AUTOSAR XML (schema 00044)
package /ComponentTypes
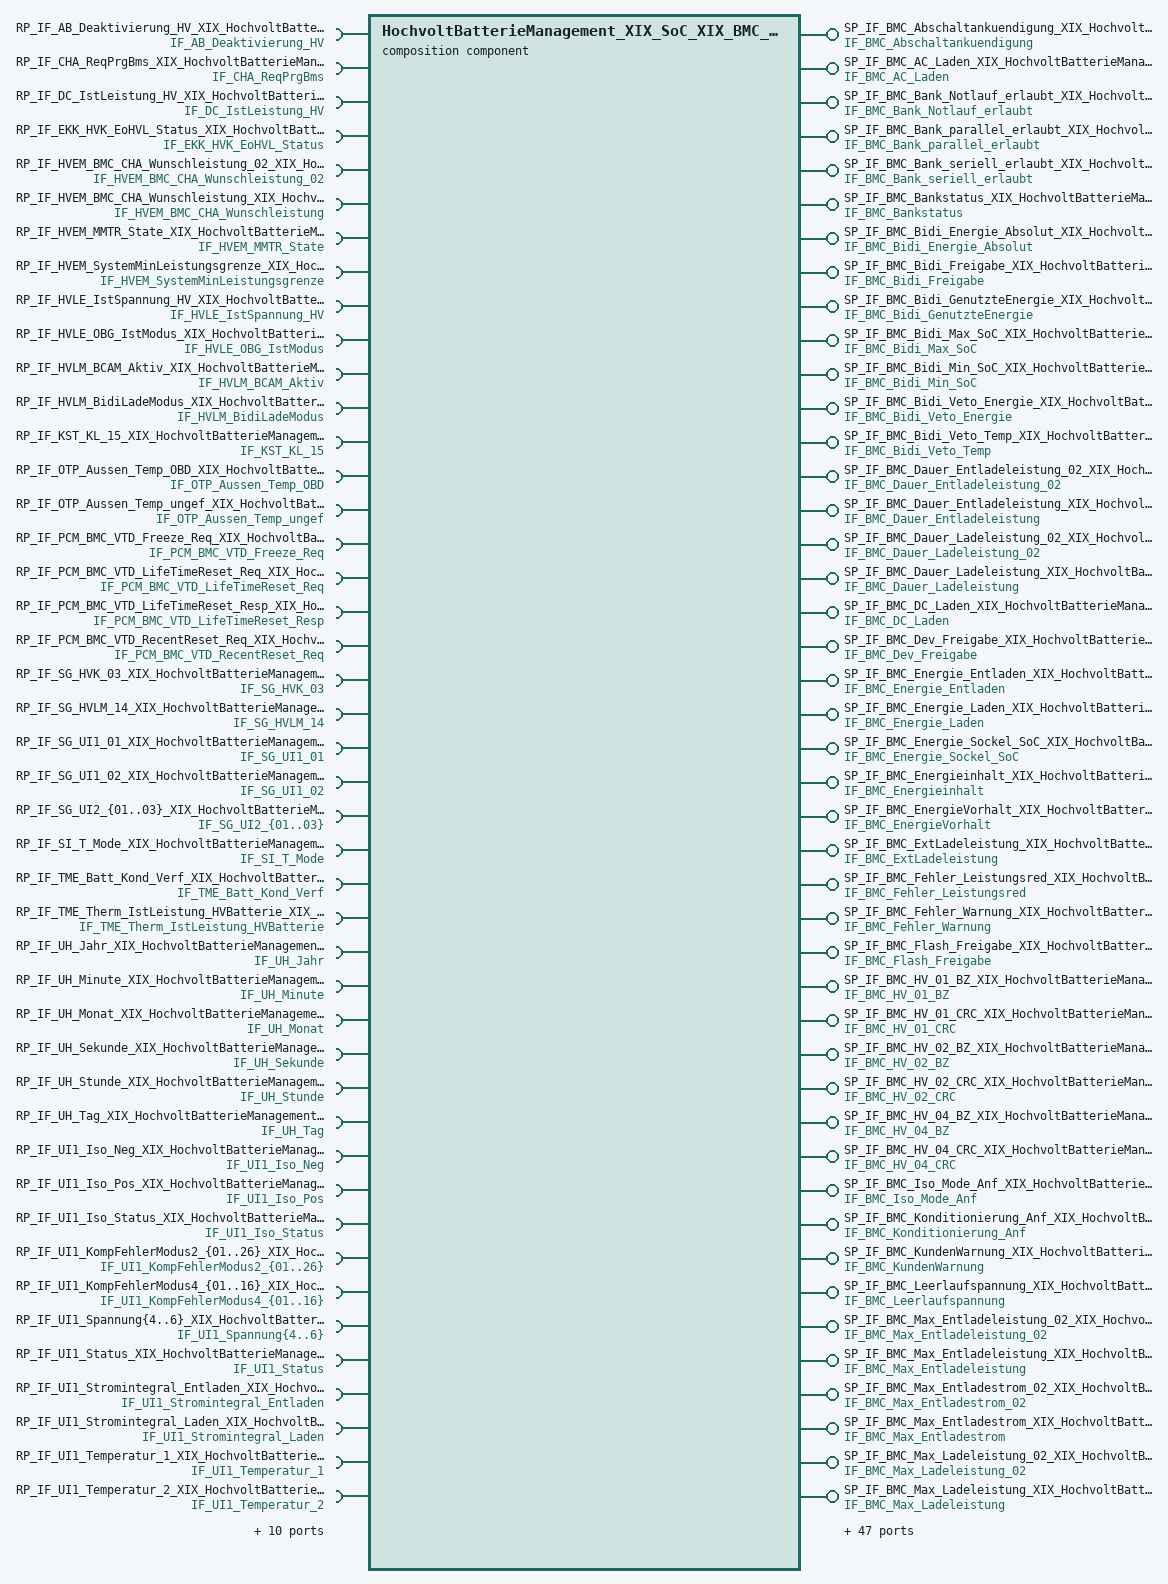
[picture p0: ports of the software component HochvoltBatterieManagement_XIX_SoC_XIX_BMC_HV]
  composition sw component type HochvoltBatterieManagement_XIX_SoC_XIX_BMC_HV
    91 x provide port:
      SP_IF_BMC_Abschaltankuendigung_XIX_HochvoltBatterieManagement_XIX_SoC_XIX_BMC_HV: nonqueued-sender-com-spec=DE_BMC_Abschaltankuendigung, provided-interface=IF_BMC_Abschaltankuendigung
      SP_IF_BMC_AC_Laden_XIX_HochvoltBatterieManagement_XIX_SoC_XIX_BMC_HV: nonqueued-sender-com-spec=DE_BMC_AC_Laden, provided-interface=IF_BMC_AC_Laden
      SP_IF_BMC_Bank_Notlauf_erlaubt_XIX_HochvoltBatterieManagement_XIX_SoC_XIX_BMC_HV: nonqueued-sender-com-spec=DE_BMC_Bank_Notlauf_erlaubt, provided-interface=IF_BMC_Bank_Notlauf_erlaubt
      SP_IF_BMC_Bank_parallel_erlaubt_XIX_HochvoltBatterieManagement_XIX_SoC_XIX_BMC_HV: nonqueued-sender-com-spec=DE_BMC_Bank_parallel_erlaubt, provided-interface=IF_BMC_Bank_parallel_erlaubt
      SP_IF_BMC_Bank_seriell_erlaubt_XIX_HochvoltBatterieManagement_XIX_SoC_XIX_BMC_HV: nonqueued-sender-com-spec=DE_BMC_Bank_seriell_erlaubt, provided-interface=IF_BMC_Bank_seriell_erlaubt
      SP_IF_BMC_Bankstatus_XIX_HochvoltBatterieManagement_XIX_SoC_XIX_BMC_HV: nonqueued-sender-com-spec=DE_BMC_Bankstatus, provided-interface=IF_BMC_Bankstatus
      SP_IF_BMC_Bidi_Energie_Absolut_XIX_HochvoltBatterieManagement_XIX_SoC_XIX_BMC_HV: nonqueued-sender-com-spec=DE_BMC_Bidi_Energie_Absolut, provided-interface=IF_BMC_Bidi_Energie_Absolut
      SP_IF_BMC_Bidi_Freigabe_XIX_HochvoltBatterieManagement_XIX_SoC_XIX_BMC_HV: nonqueued-sender-com-spec=DE_BMC_Bidi_Freigabe, provided-interface=IF_BMC_Bidi_Freigabe
      SP_IF_BMC_Bidi_GenutzteEnergie_XIX_HochvoltBatterieManagement_XIX_SoC_XIX_BMC_HV: nonqueued-sender-com-spec=DE_BMC_Bidi_GenutzteEnergie, provided-interface=IF_BMC_Bidi_GenutzteEnergie
      SP_IF_BMC_Bidi_Max_SoC_XIX_HochvoltBatterieManagement_XIX_SoC_XIX_BMC_HV: nonqueued-sender-com-spec=DE_BMC_Bidi_Max_SoC, provided-interface=IF_BMC_Bidi_Max_SoC
      SP_IF_BMC_Bidi_Min_SoC_XIX_HochvoltBatterieManagement_XIX_SoC_XIX_BMC_HV: nonqueued-sender-com-spec=DE_BMC_Bidi_Min_SoC, provided-interface=IF_BMC_Bidi_Min_SoC
      SP_IF_BMC_Bidi_Veto_Energie_XIX_HochvoltBatterieManagement_XIX_SoC_XIX_BMC_HV: nonqueued-sender-com-spec=DE_BMC_Bidi_Veto_Energie, provided-interface=IF_BMC_Bidi_Veto_Energie
      SP_IF_BMC_Bidi_Veto_Temp_XIX_HochvoltBatterieManagement_XIX_SoC_XIX_BMC_HV: nonqueued-sender-com-spec=DE_BMC_Bidi_Veto_Temp, provided-interface=IF_BMC_Bidi_Veto_Temp
      SP_IF_BMC_Dauer_Entladeleistung_02_XIX_HochvoltBatterieManagement_XIX_SoC_XIX_BMC_HV: nonqueued-sender-com-spec=DE_BMC_Dauer_Entladeleistung_02, provided-interface=IF_BMC_Dauer_Entladeleistung_02
      SP_IF_BMC_Dauer_Entladeleistung_XIX_HochvoltBatterieManagement_XIX_SoC_XIX_BMC_HV: nonqueued-sender-com-spec=DE_BMC_Dauer_Entladeleistung, provided-interface=IF_BMC_Dauer_Entladeleistung
      SP_IF_BMC_Dauer_Ladeleistung_02_XIX_HochvoltBatterieManagement_XIX_SoC_XIX_BMC_HV: nonqueued-sender-com-spec=DE_BMC_Dauer_Ladeleistung_02, provided-interface=IF_BMC_Dauer_Ladeleistung_02
      SP_IF_BMC_Dauer_Ladeleistung_XIX_HochvoltBatterieManagement_XIX_SoC_XIX_BMC_HV: nonqueued-sender-com-spec=DE_BMC_Dauer_Ladeleistung, provided-interface=IF_BMC_Dauer_Ladeleistung
      SP_IF_BMC_DC_Laden_XIX_HochvoltBatterieManagement_XIX_SoC_XIX_BMC_HV: nonqueued-sender-com-spec=DE_BMC_DC_Laden, provided-interface=IF_BMC_DC_Laden
      SP_IF_BMC_Dev_Freigabe_XIX_HochvoltBatterieManagement_XIX_SoC_XIX_BMC_HV: nonqueued-sender-com-spec=DE_BMC_Dev_Freigabe, provided-interface=IF_BMC_Dev_Freigabe
      SP_IF_BMC_Energie_Entladen_XIX_HochvoltBatterieManagement_XIX_SoC_XIX_BMC_HV: nonqueued-sender-com-spec=DE_BMC_Energie_Entladen, provided-interface=IF_BMC_Energie_Entladen
      SP_IF_BMC_Energie_Laden_XIX_HochvoltBatterieManagement_XIX_SoC_XIX_BMC_HV: nonqueued-sender-com-spec=DE_BMC_Energie_Laden, provided-interface=IF_BMC_Energie_Laden
      SP_IF_BMC_Energie_Sockel_SoC_XIX_HochvoltBatterieManagement_XIX_SoC_XIX_BMC_HV: nonqueued-sender-com-spec=DE_BMC_Energie_Sockel_SoC, provided-interface=IF_BMC_Energie_Sockel_SoC
      SP_IF_BMC_Energieinhalt_XIX_HochvoltBatterieManagement_XIX_SoC_XIX_BMC_HV: nonqueued-sender-com-spec=DE_BMC_Energieinhalt, provided-interface=IF_BMC_Energieinhalt
      SP_IF_BMC_EnergieVorhalt_XIX_HochvoltBatterieManagement_XIX_SoC_XIX_BMC_HV: nonqueued-sender-com-spec=DE_BMC_EnergieVorhalt, provided-interface=IF_BMC_EnergieVorhalt
      SP_IF_BMC_ExtLadeleistung_XIX_HochvoltBatterieManagement_XIX_SoC_XIX_BMC_HV: nonqueued-sender-com-spec=DE_BMC_ExtLadeleistung, provided-interface=IF_BMC_ExtLadeleistung
      SP_IF_BMC_Fehler_Leistungsred_XIX_HochvoltBatterieManagement_XIX_SoC_XIX_BMC_HV: nonqueued-sender-com-spec=DE_BMC_Fehler_Leistungsred, provided-interface=IF_BMC_Fehler_Leistungsred
      SP_IF_BMC_Fehler_Warnung_XIX_HochvoltBatterieManagement_XIX_SoC_XIX_BMC_HV: nonqueued-sender-com-spec=DE_BMC_Fehler_Warnung, provided-interface=IF_BMC_Fehler_Warnung
      SP_IF_BMC_Flash_Freigabe_XIX_HochvoltBatterieManagement_XIX_SoC_XIX_BMC_HV: nonqueued-sender-com-spec=DE_BMC_Flash_Freigabe, provided-interface=IF_BMC_Flash_Freigabe
      SP_IF_BMC_HV_01_BZ_XIX_HochvoltBatterieManagement_XIX_SoC_XIX_BMC_HV: nonqueued-sender-com-spec=DE_BMC_HV_01_BZ, provided-interface=IF_BMC_HV_01_BZ
      SP_IF_BMC_HV_01_CRC_XIX_HochvoltBatterieManagement_XIX_SoC_XIX_BMC_HV: nonqueued-sender-com-spec=DE_BMC_HV_01_CRC, provided-interface=IF_BMC_HV_01_CRC
      SP_IF_BMC_HV_02_BZ_XIX_HochvoltBatterieManagement_XIX_SoC_XIX_BMC_HV: nonqueued-sender-com-spec=DE_BMC_HV_02_BZ, provided-interface=IF_BMC_HV_02_BZ
      SP_IF_BMC_HV_02_CRC_XIX_HochvoltBatterieManagement_XIX_SoC_XIX_BMC_HV: nonqueued-sender-com-spec=DE_BMC_HV_02_CRC, provided-interface=IF_BMC_HV_02_CRC
      SP_IF_BMC_HV_04_BZ_XIX_HochvoltBatterieManagement_XIX_SoC_XIX_BMC_HV: nonqueued-sender-com-spec=DE_BMC_HV_04_BZ, provided-interface=IF_BMC_HV_04_BZ
      SP_IF_BMC_HV_04_CRC_XIX_HochvoltBatterieManagement_XIX_SoC_XIX_BMC_HV: nonqueued-sender-com-spec=DE_BMC_HV_04_CRC, provided-interface=IF_BMC_HV_04_CRC
      SP_IF_BMC_Iso_Mode_Anf_XIX_HochvoltBatterieManagement_XIX_SoC_XIX_BMC_HV: nonqueued-sender-com-spec=DE_BMC_Iso_Mode_Anf, provided-interface=IF_BMC_Iso_Mode_Anf
      SP_IF_BMC_Konditionierung_Anf_XIX_HochvoltBatterieManagement_XIX_SoC_XIX_BMC_HV: nonqueued-sender-com-spec=DE_BMC_Konditionierung_Anf, provided-interface=IF_BMC_Konditionierung_Anf
      SP_IF_BMC_KundenWarnung_XIX_HochvoltBatterieManagement_XIX_SoC_XIX_BMC_HV: nonqueued-sender-com-spec=DE_BMC_KundenWarnung, provided-interface=IF_BMC_KundenWarnung
      SP_IF_BMC_Leerlaufspannung_XIX_HochvoltBatterieManagement_XIX_SoC_XIX_BMC_HV: nonqueued-sender-com-spec=DE_BMC_Leerlaufspannung, provided-interface=IF_BMC_Leerlaufspannung
      SP_IF_BMC_Max_Entladeleistung_02_XIX_HochvoltBatterieManagement_XIX_SoC_XIX_BMC_HV: nonqueued-sender-com-spec=DE_BMC_Max_Entladeleistung_02, provided-interface=IF_BMC_Max_Entladeleistung_02
      SP_IF_BMC_Max_Entladeleistung_XIX_HochvoltBatterieManagement_XIX_SoC_XIX_BMC_HV: nonqueued-sender-com-spec=DE_BMC_Max_Entladeleistung, provided-interface=IF_BMC_Max_Entladeleistung
      SP_IF_BMC_Max_Entladestrom_02_XIX_HochvoltBatterieManagement_XIX_SoC_XIX_BMC_HV: nonqueued-sender-com-spec=DE_BMC_Max_Entladestrom_02, provided-interface=IF_BMC_Max_Entladestrom_02
      SP_IF_BMC_Max_Entladestrom_XIX_HochvoltBatterieManagement_XIX_SoC_XIX_BMC_HV: nonqueued-sender-com-spec=DE_BMC_Max_Entladestrom, provided-interface=IF_BMC_Max_Entladestrom
      SP_IF_BMC_Max_Ladeleistung_02_XIX_HochvoltBatterieManagement_XIX_SoC_XIX_BMC_HV: nonqueued-sender-com-spec=DE_BMC_Max_Ladeleistung_02, provided-interface=IF_BMC_Max_Ladeleistung_02
      SP_IF_BMC_Max_Ladeleistung_XIX_HochvoltBatterieManagement_XIX_SoC_XIX_BMC_HV: nonqueued-sender-com-spec=DE_BMC_Max_Ladeleistung, provided-interface=IF_BMC_Max_Ladeleistung
      SP_IF_BMC_Max_Ladestrom_02_XIX_HochvoltBatterieManagement_XIX_SoC_XIX_BMC_HV: nonqueued-sender-com-spec=DE_BMC_Max_Ladestrom_02, provided-interface=IF_BMC_Max_Ladestrom_02
      SP_IF_BMC_Max_Ladestrom_XIX_HochvoltBatterieManagement_XIX_SoC_XIX_BMC_HV: nonqueued-sender-com-spec=DE_BMC_Max_Ladestrom, provided-interface=IF_BMC_Max_Ladestrom
      SP_IF_BMC_Max_Spannung_XIX_HochvoltBatterieManagement_XIX_SoC_XIX_BMC_HV: nonqueued-sender-com-spec=DE_BMC_Max_Spannung, provided-interface=IF_BMC_Max_Spannung
      SP_IF_BMC_MaxEnergieinhalt_XIX_HochvoltBatterieManagement_XIX_SoC_XIX_BMC_HV: nonqueued-sender-com-spec=DE_BMC_MaxEnergieinhalt, provided-interface=IF_BMC_MaxEnergieinhalt
      SP_IF_BMC_Min_Spannung_XIX_HochvoltBatterieManagement_XIX_SoC_XIX_BMC_HV: nonqueued-sender-com-spec=DE_BMC_Min_Spannung, provided-interface=IF_BMC_Min_Spannung
      SP_IF_BMC_MinDyn_Entladespannung_XIX_HochvoltBatterieManagement_XIX_SoC_XIX_BMC_HV: nonqueued-sender-com-spec=DE_BMC_MinDyn_Entladespannung, provided-interface=IF_BMC_MinDyn_Entladespannung
      SP_IF_BMC_MinDyn_Ladespannung_XIX_HochvoltBatterieManagement_XIX_SoC_XIX_BMC_HV: nonqueued-sender-com-spec=DE_BMC_MinDyn_Ladespannung, provided-interface=IF_BMC_MinDyn_Ladespannung
      SP_IF_BMC_MMTR_Status_XIX_HochvoltBatterieManagement_XIX_SoC_XIX_BMC_HV: nonqueued-sender-com-spec=DE_BMC_MMTR_Status, provided-interface=IF_BMC_MMTR_Status
      SP_IF_BMC_NutzbareKapazitaet_XIX_HochvoltBatterieManagement_XIX_SoC_XIX_BMC_HV: nonqueued-sender-com-spec=DE_BMC_NutzbareKapazitaet, provided-interface=IF_BMC_NutzbareKapazitaet
      SP_IF_BMC_NutzbarerSOC_XIX_HochvoltBatterieManagement_XIX_SoC_XIX_BMC_HV: nonqueued-sender-com-spec=DE_BMC_NutzbarerSOC, provided-interface=IF_BMC_NutzbarerSOC
      SP_IF_BMC_PCM_VTD_Freeze_Req_XIX_HochvoltBatterieManagement_XIX_SoC_XIX_BMC_HV: nonqueued-sender-com-spec=DE_BMC_PCM_VTD_Freeze_Req, provided-interface=IF_BMC_PCM_VTD_Freeze_Req
      SP_IF_BMC_PCM_VTD_LifeTimeReset_Req_XIX_HochvoltBatterieManagement_XIX_SoC_XIX_BMC_HV: nonqueued-sender-com-spec=DE_BMC_PCM_VTD_LifeTimeReset_Req, provided-interface=IF_BMC_PCM_VTD_LifeTimeReset_Req
      SP_IF_BMC_PCM_VTD_LifeTimeReset_Resp_XIX_HochvoltBatterieManagement_XIX_SoC_XIX_BMC_HV: nonqueued-sender-com-spec=DE_BMC_PCM_VTD_LifeTimeReset_Resp, provided-interface=IF_BMC_PCM_VTD_LifeTimeReset_Resp
      SP_IF_BMC_PCM_VTD_RecentReset_Req_XIX_HochvoltBatterieManagement_XIX_SoC_XIX_BMC_HV: nonqueued-sender-com-spec=DE_BMC_PCM_VTD_RecentReset_Req, provided-interface=IF_BMC_PCM_VTD_RecentReset_Req
      SP_IF_BMC_PerfInd_Entladen_XIX_HochvoltBatterieManagement_XIX_SoC_XIX_BMC_HV: nonqueued-sender-com-spec=DE_BMC_PerfInd_Entladen, provided-interface=IF_BMC_PerfInd_Entladen
      SP_IF_BMC_PerfInd_Laden_XIX_HochvoltBatterieManagement_XIX_SoC_XIX_BMC_HV: nonqueued-sender-com-spec=DE_BMC_PerfInd_Laden, provided-interface=IF_BMC_PerfInd_Laden
      SP_IF_BMC_PredLeistung_StuetzungNV_XIX_HochvoltBatterieManagement_XIX_SoC_XIX_BMC_HV: nonqueued-sender-com-spec=DE_BMC_PredLeistung_StuetzungNV, provided-interface=IF_BMC_PredLeistung_StuetzungNV
      SP_IF_BMC_Range_Indikator_XIX_HochvoltBatterieManagement_XIX_SoC_XIX_BMC_HV: nonqueued-sender-com-spec=DE_BMC_Range_Indikator, provided-interface=IF_BMC_Range_Indikator
      SP_IF_BMC_Rekuperation_Ueberlauf_XIX_HochvoltBatterieManagement_XIX_SoC_XIX_BMC_HV: nonqueued-sender-com-spec=DE_BMC_Rekuperation_Ueberlauf, provided-interface=IF_BMC_Rekuperation_Ueberlauf
      SP_IF_BMC_Rekuperation_XIX_HochvoltBatterieManagement_XIX_SoC_XIX_BMC_HV: nonqueued-sender-com-spec=DE_BMC_Rekuperation, provided-interface=IF_BMC_Rekuperation
      SP_IF_BMC_RuecklaufTemperatur_XIX_HochvoltBatterieManagement_XIX_SoC_XIX_BMC_HV: nonqueued-sender-com-spec=DE_BMC_RuecklaufTemperatur, provided-interface=IF_BMC_RuecklaufTemperatur
      SP_IF_BMC_Spannung_DC_Ladesaeule_XIX_HochvoltBatterieManagement_XIX_SoC_XIX_BMC_HV: nonqueued-sender-com-spec=DE_BMC_Spannung_DC_Ladesaeule, provided-interface=IF_BMC_Spannung_DC_Ladesaeule
      SP_IF_BMC_Spannung_XIX_HochvoltBatterieManagement_XIX_SoC_XIX_BMC_HV: nonqueued-sender-com-spec=DE_BMC_Spannung, provided-interface=IF_BMC_Spannung
      SP_IF_BMC_Spannung_ZwischenKreis_2_XIX_HochvoltBatterieManagement_XIX_SoC_XIX_BMC_HV: nonqueued-sender-com-spec=DE_BMC_Spannung_ZwischenKreis_2, provided-interface=IF_BMC_Spannung_ZwischenKreis_2
      SP_IF_BMC_Spannung_ZwischenKreis_XIX_HochvoltBatterieManagement_XIX_SoC_XIX_BMC_HV: nonqueued-sender-com-spec=DE_BMC_Spannung_ZwischenKreis, provided-interface=IF_BMC_Spannung_ZwischenKreis
      SP_IF_BMC_Status_DCLS_XIX_HochvoltBatterieManagement_XIX_SoC_XIX_BMC_HV: nonqueued-sender-com-spec=DE_BMC_Status_DCLS, provided-interface=IF_BMC_Status_DCLS
      SP_IF_BMC_Strom_02_XIX_HochvoltBatterieManagement_XIX_SoC_XIX_BMC_HV: nonqueued-sender-com-spec=DE_BMC_Strom_02, provided-interface=IF_BMC_Strom_02
      SP_IF_BMC_Strom_XIX_HochvoltBatterieManagement_XIX_SoC_XIX_BMC_HV: nonqueued-sender-com-spec=DE_BMC_Strom, provided-interface=IF_BMC_Strom
      SP_IF_BMC_TechnischerSOC_XIX_HochvoltBatterieManagement_XIX_SoC_XIX_BMC_HV: nonqueued-sender-com-spec=DE_BMC_TechnischerSOC, provided-interface=IF_BMC_TechnischerSOC
      SP_IF_BMC_Temperatur_XIX_HochvoltBatterieManagement_XIX_SoC_XIX_BMC_HV: nonqueued-sender-com-spec=DE_BMC_Temperatur, provided-interface=IF_BMC_Temperatur
      SP_IF_BMC_ThermAuslastung_XIX_HochvoltBatterieManagement_XIX_SoC_XIX_BMC_HV: nonqueued-sender-com-spec=DE_BMC_ThermAuslastung, provided-interface=IF_BMC_ThermAuslastung
      SP_IF_BMC_ThermSpreizung_XIX_HochvoltBatterieManagement_XIX_SoC_XIX_BMC_HV: nonqueued-sender-com-spec=DE_BMC_ThermSpreizung, provided-interface=IF_BMC_ThermSpreizung
      SP_IF_BMC_UBE_Indik_last_update_km_XIX_HochvoltBatterieManagement_XIX_SoC_XIX_BMC_HV: nonqueued-sender-com-spec=DE_BMC_UBE_Indik_last_update_km, provided-interface=IF_BMC_UBE_Indik_last_update_km
      SP_IF_BMC_UBE_Indikator_XIX_HochvoltBatterieManagement_XIX_SoC_XIX_BMC_HV: nonqueued-sender-com-spec=DE_BMC_UBE_Indikator, provided-interface=IF_BMC_UBE_Indikator
      SP_IF_BMC_UI1_Spannung1_Schalt_Anf_XIX_HochvoltBatterieManagement_XIX_SoC_XIX_BMC_HV: nonqueued-sender-com-spec=DE_BMC_UI1_Spannung1_Schalt_Anf, provided-interface=IF_BMC_UI1_Spannung1_Schalt_Anf
      SP_IF_BMC_UI1_Spannung2_Schalt_Anf_XIX_HochvoltBatterieManagement_XIX_SoC_XIX_BMC_HV: nonqueued-sender-com-spec=DE_BMC_UI1_Spannung2_Schalt_Anf, provided-interface=IF_BMC_UI1_Spannung2_Schalt_Anf
      SP_IF_BMC_UI2_Spannung1_Schalt_Anf_XIX_HochvoltBatterieManagement_XIX_SoC_XIX_BMC_HV: nonqueued-sender-com-spec=DE_BMC_UI2_Spannung1_Schalt_Anf, provided-interface=IF_BMC_UI2_Spannung1_Schalt_Anf
      SP_IF_BMC_UI2_Spannung2_Schalt_Anf_XIX_HochvoltBatterieManagement_XIX_SoC_XIX_BMC_HV: nonqueued-sender-com-spec=DE_BMC_UI2_Spannung2_Schalt_Anf, provided-interface=IF_BMC_UI2_Spannung2_Schalt_Anf
      SP_IF_BMC_Unterboden_Warnung_XIX_HochvoltBatterieManagement_XIX_SoC_XIX_BMC_HV: nonqueued-sender-com-spec=DE_BMC_Unterboden_Warnung, provided-interface=IF_BMC_Unterboden_Warnung
      SP_IF_BMC_Verbauinfo_ACSchuetz_XIX_HochvoltBatterieManagement_XIX_SoC_XIX_BMC_HV: nonqueued-sender-com-spec=DE_BMC_Verbauinfo_ACSchuetz, provided-interface=IF_BMC_Verbauinfo_ACSchuetz
      SP_IF_BMC_Verbauinfo_Bank_XIX_HochvoltBatterieManagement_XIX_SoC_XIX_BMC_HV: nonqueued-sender-com-spec=DE_BMC_Verbauinfo_Bank, provided-interface=IF_BMC_Verbauinfo_Bank
      SP_IF_BMC_Verbrauch_Ueberlauf_XIX_HochvoltBatterieManagement_XIX_SoC_XIX_BMC_HV: nonqueued-sender-com-spec=DE_BMC_Verbrauch_Ueberlauf, provided-interface=IF_BMC_Verbrauch_Ueberlauf
      SP_IF_BMC_Verbrauch_XIX_HochvoltBatterieManagement_XIX_SoC_XIX_BMC_HV: nonqueued-sender-com-spec=DE_BMC_Verbrauch, provided-interface=IF_BMC_Verbrauch
      SP_IF_BMC_VerlustEnergie_XIX_HochvoltBatterieManagement_XIX_SoC_XIX_BMC_HV: nonqueued-sender-com-spec=DE_BMC_VerlustEnergie, provided-interface=IF_BMC_VerlustEnergie
      SP_IF_BMC_VorlaufTemperatur_XIX_HochvoltBatterieManagement_XIX_SoC_XIX_BMC_HV: nonqueued-sender-com-spec=DE_BMC_VorlaufTemperatur, provided-interface=IF_BMC_VorlaufTemperatur
      SP_IF_BMC_ZellTemp_virtuell_max_XIX_HochvoltBatterieManagement_XIX_SoC_XIX_BMC_HV: nonqueued-sender-com-spec=DE_BMC_ZellTemp_virtuell_max, provided-interface=IF_BMC_ZellTemp_virtuell_max
      SP_IF_BMC_ZellTemp_virtuell_min_XIX_HochvoltBatterieManagement_XIX_SoC_XIX_BMC_HV: nonqueued-sender-com-spec=DE_BMC_ZellTemp_virtuell_min, provided-interface=IF_BMC_ZellTemp_virtuell_min
    138 x require port:
      RP_IF_AB_Deaktivierung_HV_XIX_HochvoltBatterieManagement_XIX_SoC_XIX_BMC_HV: nonqueued-receiver-com-spec=DE_AB_Deaktivierung_HV, required-interface=IF_AB_Deaktivierung_HV
      RP_IF_CHA_ReqPrgBms_XIX_HochvoltBatterieManagement_XIX_SoC_XIX_BMC_HV: nonqueued-receiver-com-spec=DE_CHA_ReqPrgBms, required-interface=IF_CHA_ReqPrgBms
      RP_IF_DC_IstLeistung_HV_XIX_HochvoltBatterieManagement_XIX_SoC_XIX_BMC_HV: nonqueued-receiver-com-spec=DE_DC_IstLeistung_HV, required-interface=IF_DC_IstLeistung_HV
      RP_IF_EKK_HVK_EoHVL_Status_XIX_HochvoltBatterieManagement_XIX_SoC_XIX_BMC_HV: nonqueued-receiver-com-spec=DE_EKK_HVK_EoHVL_Status, required-interface=IF_EKK_HVK_EoHVL_Status
      RP_IF_HVEM_BMC_CHA_Wunschleistung_02_XIX_HochvoltBatterieManagement_XIX_SoC_XIX_BMC_HV: nonqueued-receiver-com-spec=DE_HVEM_BMC_CHA_Wunschleistung_02, required-interface=IF_HVEM_BMC_CHA_Wunschleistung_02
      RP_IF_HVEM_BMC_CHA_Wunschleistung_XIX_HochvoltBatterieManagement_XIX_SoC_XIX_BMC_HV: nonqueued-receiver-com-spec=DE_HVEM_BMC_CHA_Wunschleistung, required-interface=IF_HVEM_BMC_CHA_Wunschleistung
      RP_IF_HVEM_MMTR_State_XIX_HochvoltBatterieManagement_XIX_SoC_XIX_BMC_HV: nonqueued-receiver-com-spec=DE_HVEM_MMTR_State, required-interface=IF_HVEM_MMTR_State
      RP_IF_HVEM_SystemMinLeistungsgrenze_XIX_HochvoltBatterieManagement_XIX_SoC_XIX_BMC_HV: nonqueued-receiver-com-spec=DE_HVEM_SystemMinLeistungsgrenze, required-interface=IF_HVEM_SystemMinLeistungsgrenze
      RP_IF_HVLE_IstSpannung_HV_XIX_HochvoltBatterieManagement_XIX_SoC_XIX_BMC_HV: nonqueued-receiver-com-spec=DE_HVLE_IstSpannung_HV, required-interface=IF_HVLE_IstSpannung_HV
      RP_IF_HVLE_OBG_IstModus_XIX_HochvoltBatterieManagement_XIX_SoC_XIX_BMC_HV: nonqueued-receiver-com-spec=DE_HVLE_OBG_IstModus, required-interface=IF_HVLE_OBG_IstModus
      RP_IF_HVLM_BCAM_Aktiv_XIX_HochvoltBatterieManagement_XIX_SoC_XIX_BMC_HV: nonqueued-receiver-com-spec=DE_HVLM_BCAM_Aktiv, required-interface=IF_HVLM_BCAM_Aktiv
      RP_IF_HVLM_BidiLadeModus_XIX_HochvoltBatterieManagement_XIX_SoC_XIX_BMC_HV: nonqueued-receiver-com-spec=DE_HVLM_BidiLadeModus, required-interface=IF_HVLM_BidiLadeModus
      RP_IF_KST_KL_15_XIX_HochvoltBatterieManagement_XIX_SoC_XIX_BMC_HV: nonqueued-receiver-com-spec=DE_KST_KL_15, required-interface=IF_KST_KL_15
      RP_IF_OTP_Aussen_Temp_OBD_XIX_HochvoltBatterieManagement_XIX_SoC_XIX_BMC_HV: nonqueued-receiver-com-spec=DE_OTP_Aussen_Temp_OBD, required-interface=IF_OTP_Aussen_Temp_OBD
      RP_IF_OTP_Aussen_Temp_ungef_XIX_HochvoltBatterieManagement_XIX_SoC_XIX_BMC_HV: nonqueued-receiver-com-spec=DE_OTP_Aussen_Temp_ungef, required-interface=IF_OTP_Aussen_Temp_ungef
      RP_IF_PCM_BMC_VTD_Freeze_Req_XIX_HochvoltBatterieManagement_XIX_SoC_XIX_BMC_HV: nonqueued-receiver-com-spec=DE_PCM_BMC_VTD_Freeze_Req, required-interface=IF_PCM_BMC_VTD_Freeze_Req
      RP_IF_PCM_BMC_VTD_LifeTimeReset_Req_XIX_HochvoltBatterieManagement_XIX_SoC_XIX_BMC_HV: nonqueued-receiver-com-spec=DE_PCM_BMC_VTD_LifeTimeReset_Req, required-interface=IF_PCM_BMC_VTD_LifeTimeReset_Req
      RP_IF_PCM_BMC_VTD_LifeTimeReset_Resp_XIX_HochvoltBatterieManagement_XIX_SoC_XIX_BMC_HV: nonqueued-receiver-com-spec=DE_PCM_BMC_VTD_LifeTimeReset_Resp, required-interface=IF_PCM_BMC_VTD_LifeTimeReset_Resp
      RP_IF_PCM_BMC_VTD_RecentReset_Req_XIX_HochvoltBatterieManagement_XIX_SoC_XIX_BMC_HV: nonqueued-receiver-com-spec=DE_PCM_BMC_VTD_RecentReset_Req, required-interface=IF_PCM_BMC_VTD_RecentReset_Req
      RP_IF_SG_HVK_03_XIX_HochvoltBatterieManagement_XIX_SoC_XIX_BMC_HV: nonqueued-receiver-com-spec=DE_SG_HVK_03, required-interface=IF_SG_HVK_03
      RP_IF_SG_HVLM_14_XIX_HochvoltBatterieManagement_XIX_SoC_XIX_BMC_HV: nonqueued-receiver-com-spec=DE_SG_HVLM_14, required-interface=IF_SG_HVLM_14
      RP_IF_SG_UI1_01_XIX_HochvoltBatterieManagement_XIX_SoC_XIX_BMC_HV: nonqueued-receiver-com-spec=DE_SG_UI1_01, required-interface=IF_SG_UI1_01
      RP_IF_SG_UI1_02_XIX_HochvoltBatterieManagement_XIX_SoC_XIX_BMC_HV: nonqueued-receiver-com-spec=DE_SG_UI1_02, required-interface=IF_SG_UI1_02
      RP_IF_SG_UI2_{01..03}_XIX_HochvoltBatterieManagement_XIX_SoC_XIX_BMC_HV: nonqueued-receiver-com-spec=DE_SG_UI2_{01..03}, required-interface=IF_SG_UI2_{01..03}
      RP_IF_SI_T_Mode_XIX_HochvoltBatterieManagement_XIX_SoC_XIX_BMC_HV: nonqueued-receiver-com-spec=DE_SI_T_Mode, required-interface=IF_SI_T_Mode
      RP_IF_TME_Batt_Kond_Verf_XIX_HochvoltBatterieManagement_XIX_SoC_XIX_BMC_HV: nonqueued-receiver-com-spec=DE_TME_Batt_Kond_Verf, required-interface=IF_TME_Batt_Kond_Verf
      RP_IF_TME_Therm_IstLeistung_HVBatterie_XIX_HochvoltBatterieManagement_XIX_SoC_XIX_BMC_HV: nonqueued-receiver-com-spec=DE_TME_Therm_IstLeistung_HVBatterie, required-interface=IF_TME_Therm_IstLeistung_HVBatterie
      RP_IF_UH_Jahr_XIX_HochvoltBatterieManagement_XIX_SoC_XIX_BMC_HV: nonqueued-receiver-com-spec=DE_UH_Jahr, required-interface=IF_UH_Jahr
      RP_IF_UH_Minute_XIX_HochvoltBatterieManagement_XIX_SoC_XIX_BMC_HV: nonqueued-receiver-com-spec=DE_UH_Minute, required-interface=IF_UH_Minute
      RP_IF_UH_Monat_XIX_HochvoltBatterieManagement_XIX_SoC_XIX_BMC_HV: nonqueued-receiver-com-spec=DE_UH_Monat, required-interface=IF_UH_Monat
      RP_IF_UH_Sekunde_XIX_HochvoltBatterieManagement_XIX_SoC_XIX_BMC_HV: nonqueued-receiver-com-spec=DE_UH_Sekunde, required-interface=IF_UH_Sekunde
      RP_IF_UH_Stunde_XIX_HochvoltBatterieManagement_XIX_SoC_XIX_BMC_HV: nonqueued-receiver-com-spec=DE_UH_Stunde, required-interface=IF_UH_Stunde
      RP_IF_UH_Tag_XIX_HochvoltBatterieManagement_XIX_SoC_XIX_BMC_HV: nonqueued-receiver-com-spec=DE_UH_Tag, required-interface=IF_UH_Tag
      RP_IF_UI1_Iso_Neg_XIX_HochvoltBatterieManagement_XIX_SoC_XIX_BMC_HV: nonqueued-receiver-com-spec=DE_UI1_Iso_Neg, required-interface=IF_UI1_Iso_Neg
      RP_IF_UI1_Iso_Pos_XIX_HochvoltBatterieManagement_XIX_SoC_XIX_BMC_HV: nonqueued-receiver-com-spec=DE_UI1_Iso_Pos, required-interface=IF_UI1_Iso_Pos
      RP_IF_UI1_Iso_Status_XIX_HochvoltBatterieManagement_XIX_SoC_XIX_BMC_HV: nonqueued-receiver-com-spec=DE_UI1_Iso_Status, required-interface=IF_UI1_Iso_Status
      RP_IF_UI1_KompFehlerModus2_{01..26}_XIX_HochvoltBatterieManagement_XIX_SoC_XIX_BMC_HV: nonqueued-receiver-com-spec=DE_UI1_KompFehlerModus2_{01..26}, required-interface=IF_UI1_KompFehlerModus2_{01..26}
      RP_IF_UI1_KompFehlerModus4_{01..16}_XIX_HochvoltBatterieManagement_XIX_SoC_XIX_BMC_HV: nonqueued-receiver-com-spec=DE_UI1_KompFehlerModus4_{01..16}, required-interface=IF_UI1_KompFehlerModus4_{01..16}
      RP_IF_UI1_Spannung{4..6}_XIX_HochvoltBatterieManagement_XIX_SoC_XIX_BMC_HV: nonqueued-receiver-com-spec=DE_UI1_Spannung{4..6}, required-interface=IF_UI1_Spannung{4..6}
      RP_IF_UI1_Status_XIX_HochvoltBatterieManagement_XIX_SoC_XIX_BMC_HV: nonqueued-receiver-com-spec=DE_UI1_Status, required-interface=IF_UI1_Status
      RP_IF_UI1_Stromintegral_Entladen_XIX_HochvoltBatterieManagement_XIX_SoC_XIX_BMC_HV: nonqueued-receiver-com-spec=DE_UI1_Stromintegral_Entladen, required-interface=IF_UI1_Stromintegral_Entladen
      RP_IF_UI1_Stromintegral_Laden_XIX_HochvoltBatterieManagement_XIX_SoC_XIX_BMC_HV: nonqueued-receiver-com-spec=DE_UI1_Stromintegral_Laden, required-interface=IF_UI1_Stromintegral_Laden
      RP_IF_UI1_Temperatur_1_XIX_HochvoltBatterieManagement_XIX_SoC_XIX_BMC_HV: nonqueued-receiver-com-spec=DE_UI1_Temperatur_1, required-interface=IF_UI1_Temperatur_1
      RP_IF_UI1_Temperatur_2_XIX_HochvoltBatterieManagement_XIX_SoC_XIX_BMC_HV: nonqueued-receiver-com-spec=DE_UI1_Temperatur_2, required-interface=IF_UI1_Temperatur_2
      RP_IF_UI2_KompFehlerModus2_{01..26}_XIX_HochvoltBatterieManagement_XIX_SoC_XIX_BMC_HV: nonqueued-receiver-com-spec=DE_UI2_KompFehlerModus2_{01..26}, required-interface=IF_UI2_KompFehlerModus2_{01..26}
      RP_IF_UI2_KompFehlerModus4_{01..16}_XIX_HochvoltBatterieManagement_XIX_SoC_XIX_BMC_HV: nonqueued-receiver-com-spec=DE_UI2_KompFehlerModus4_{01..16}, required-interface=IF_UI2_KompFehlerModus4_{01..16}
      RP_IF_UI2_Status_XIX_HochvoltBatterieManagement_XIX_SoC_XIX_BMC_HV: nonqueued-receiver-com-spec=DE_UI2_Status, required-interface=IF_UI2_Status
      RP_IF_UI2_Stromintegral_Entladen_XIX_HochvoltBatterieManagement_XIX_SoC_XIX_BMC_HV: nonqueued-receiver-com-spec=DE_UI2_Stromintegral_Entladen, required-interface=IF_UI2_Stromintegral_Entladen
      RP_IF_UI2_Stromintegral_Laden_XIX_HochvoltBatterieManagement_XIX_SoC_XIX_BMC_HV: nonqueued-receiver-com-spec=DE_UI2_Stromintegral_Laden, required-interface=IF_UI2_Stromintegral_Laden
      RP_IF_UI2_Temperatur_1_XIX_HochvoltBatterieManagement_XIX_SoC_XIX_BMC_HV: nonqueued-receiver-com-spec=DE_UI2_Temperatur_1, required-interface=IF_UI2_Temperatur_1
      RP_IF_UI2_Temperatur_2_XIX_HochvoltBatterieManagement_XIX_SoC_XIX_BMC_HV: nonqueued-receiver-com-spec=DE_UI2_Temperatur_2, required-interface=IF_UI2_Temperatur_2
      RP_IF_ZM_HV_Auszeit_HiRes_XIX_HochvoltBatterieManagement_XIX_SoC_XIX_BMC_HV: nonqueued-receiver-com-spec=DE_ZM_HV_Auszeit_HiRes, required-interface=IF_ZM_HV_Auszeit_HiRes
      RP_IF_ZM_HV_Auszeit_Status_XIX_HochvoltBatterieManagement_XIX_SoC_XIX_BMC_HV: nonqueued-receiver-com-spec=DE_ZM_HV_Auszeit_Status, required-interface=IF_ZM_HV_Auszeit_Status
      RP_IF_ZM_HV_Auszeit_XIX_HochvoltBatterieManagement_XIX_SoC_XIX_BMC_HV: nonqueued-receiver-com-spec=DE_ZM_HV_Auszeit, required-interface=IF_ZM_HV_Auszeit
